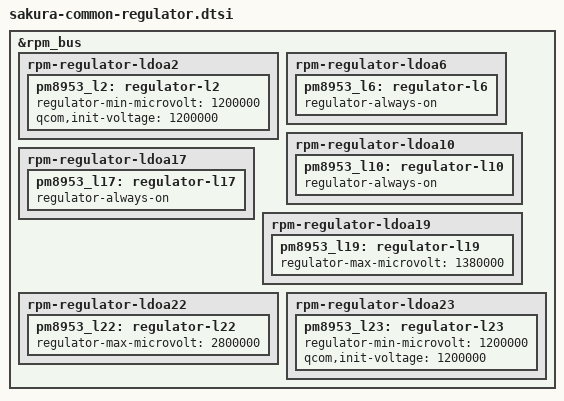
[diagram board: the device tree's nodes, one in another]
/* msm8953-regulator */
&rpm_bus {
	rpm-regulator-ldoa2 {
		pm8953_l2: regulator-l2 {
			regulator-min-microvolt = <1200000>;
			qcom,init-voltage = <1200000>;
		};
	};

	rpm-regulator-ldoa6 {
		pm8953_l6: regulator-l6 {
            regulator-always-on;
		};
	};

	rpm-regulator-ldoa10 {
		pm8953_l10: regulator-l10 {
            regulator-always-on;
		};
	};

	rpm-regulator-ldoa17 {
		pm8953_l17: regulator-l17 {
			regulator-always-on;
		};
	};

	rpm-regulator-ldoa19 {
		pm8953_l19: regulator-l19 {
			regulator-max-microvolt = <1380000>;
		};
	};

	rpm-regulator-ldoa22 {
		pm8953_l22: regulator-l22 {
			regulator-max-microvolt = <2800000>;
		};
	};

	rpm-regulator-ldoa23 {
		pm8953_l23: regulator-l23 {
			regulator-min-microvolt = <1200000>;
			qcom,init-voltage = <1200000>;
		};
	};
};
